# EFM32WG980F256 register map
File version: 4.0.0
CPU: CM4 r0p1, little endian, MPU, FPU, 3 interrupt priority bits
Registers are 32-bit, read-write, reset 0x0 unless marked. A register's access mark holds for its fields unless they carry their own. Offsets are from the block's base; [hi:lo] are bit positions; {n}, {i} and the like mark numbered series.

## VCMP
Base 0x40000000
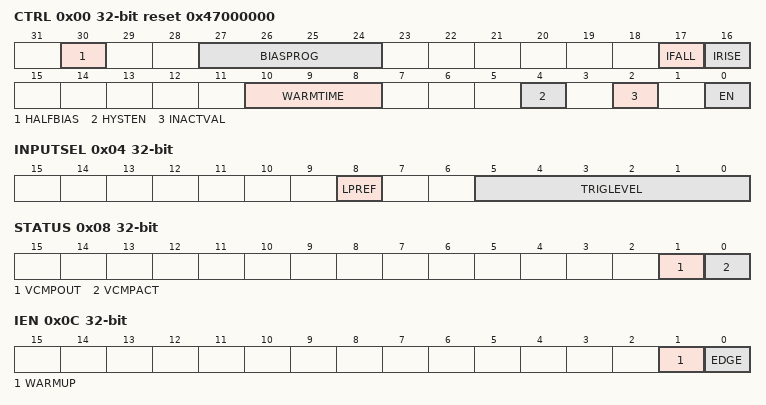
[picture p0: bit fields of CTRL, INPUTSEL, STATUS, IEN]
0x00 CTRL reset 0x47000000 — Control Register
  [30] HALFBIAS — Half Bias Current
  [27:24] BIASPROG — VCMP Bias Programming Value
  [17] IFALL — Falling Edge Interrupt Sense
  [16] IRISE — Rising Edge Interrupt Sense
  [10:8] WARMTIME — Warm-Up Time
    0=4CYCLES (4 HFPERCLK cycles); 1=8CYCLES (8 HFPERCLK cycles); 2=16CYCLES (16 HFPERCLK cycles); 3=32CYCLES (32 HFPERCLK cycles); 4=64CYCLES (64 HFPERCLK cycles); 5=128CYCLES (128 HFPERCLK cycles); 6=256CYCLES (256 HFPERCLK cycles); 7=512CYCLES (512 HFPERCLK cycles)
  [4] HYSTEN — Hysteresis Enable
  [2] INACTVAL — Inactive Value
  [0] EN — Voltage Supply Comparator Enable
0x04 INPUTSEL — Input Selection Register
  [8] LPREF — Low Power Reference
  [5:0] TRIGLEVEL — Trigger Level
0x08 STATUS ro
  [1] VCMPOUT — Voltage Supply Comparator Output
  [0] VCMPACT — Voltage Supply Comparator Active
0x0C IEN — Interrupt Enable Register
  [1] WARMUP — Warm-up Interrupt Enable
  [0] EDGE — Edge Trigger Interrupt Enable
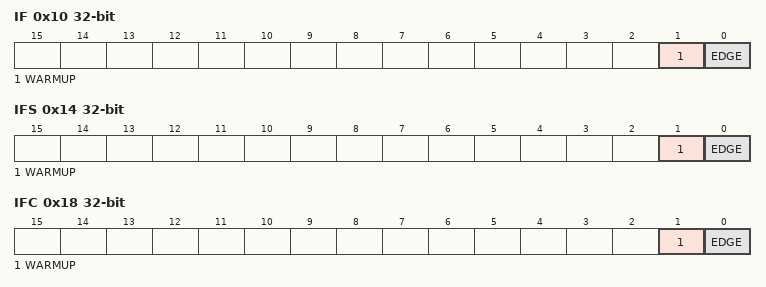
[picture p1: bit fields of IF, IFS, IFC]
0x10 IF ro — Interrupt Flag Register
  [1] WARMUP — Warm-up Interrupt Flag
  [0] EDGE — Edge Triggered Interrupt Flag
0x14 IFS wo — Interrupt Flag Set Register
  [1] WARMUP — Warm-up Interrupt Flag Set
  [0] EDGE — Edge Triggered Interrupt Flag Set
0x18 IFC wo — Interrupt Flag Clear Register
  [1] WARMUP — Warm-up Interrupt Flag Clear
  [0] EDGE — Edge Triggered Interrupt Flag Clear

## PRS
Base 0x400CC000
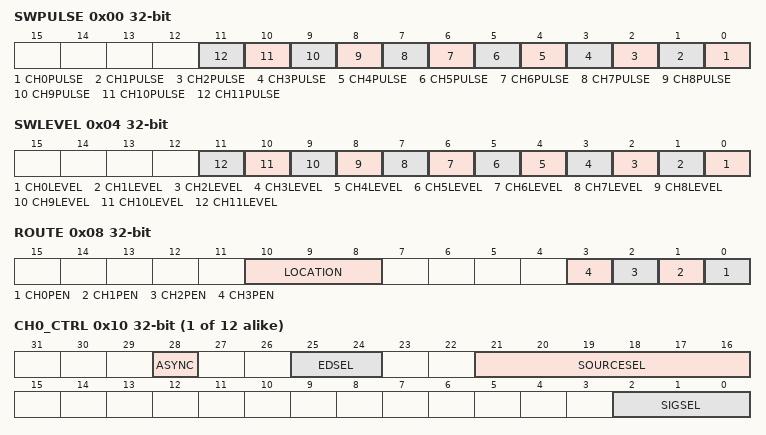
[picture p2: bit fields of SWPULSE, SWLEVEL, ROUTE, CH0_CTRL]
0x00 SWPULSE wo — Software Pulse Register
  [n] CH{n}PULSE (n=0..11) — Channel {n} Pulse Generation
0x04 SWLEVEL — Software Level Register
  [n] CH{n}LEVEL (n=0..11) — Channel {n} Software Level
0x08 ROUTE — I/O Routing Register
  [10:8] LOCATION — I/O Location
    0=LOC0 (Location 0); 1=LOC1 (Location 1)
  [n] CH{n}PEN (n=0..3) — CH{n} Pin Enable
{0x10+4i} CH{i}_CTRL (i=0..11) — Channel Control Register
  [28] ASYNC — Asynchronous reflex
  [25:24] EDSEL — Edge Detect Select
    0=OFF (Signal is left as it is); 1=POSEDGE (A one HFPERCLK cycle pulse is generated for every positive edge of the incoming signal); 2=NEGEDGE (A one HFPERCLK clock cycle pulse is generated for every negative edge of the incoming signal); 3=BOTHEDGES (A one HFPERCLK clock cycle pulse is generated for every edge of the incoming signal)
  [21:16] SOURCESEL — Source Select
    0=NONE (No source selected); 1=VCMP (Voltage Comparator); 2=ACMP0 (Analog Comparator 0); 3=ACMP1 (Analog Comparator 1); 6=DAC0 (Digital to Analog Converter 0); 8=ADC0 (Analog to Digital Converter 0); 16=USART0 (Universal Synchronous/Asynchronous Receiver/Transmitter 0); 17=USART1 (Universal Synchronous/Asynchronous Receiver/Transmitter 1); 18=USART2 (Universal Synchronous/Asynchronous Receiver/Transmitter 2); {v}=TIMER{v-28} (v=28..31); 36=USB (Universal Serial Bus Interface); 40=RTC (Real-Time Counter); 41=UART0 (Universal Asynchronous Receiver/Transmitter 0); 42=UART1 (Universal Asynchronous Receiver/Transmitter 1); 48=GPIOL (General purpose Input/Output); 49=GPIOH (General purpose Input/Output); 52=LETIMER0 (Low Energy Timer 0); 55=BURTC (Backup RTC); 57=LESENSEL (Low Energy Sensor Interface); 58=LESENSEH (Low Energy Sensor Interface); 59=LESENSED (Low Energy Sensor Interface)
  [2:0] SIGSEL — Signal Select

## LCD
Base 0x4008A000
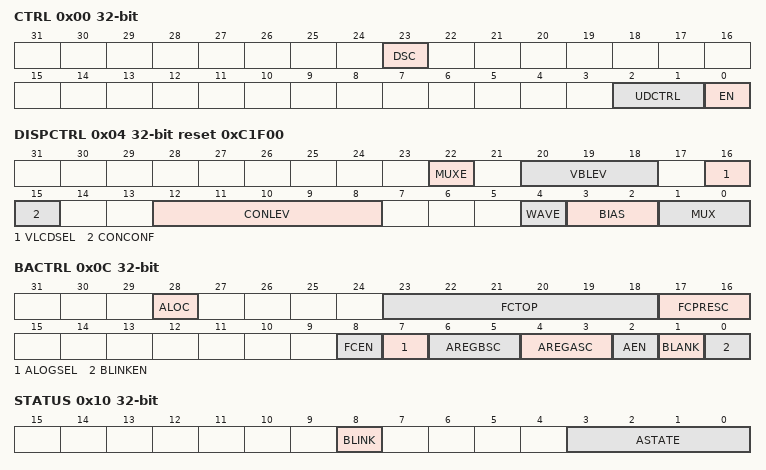
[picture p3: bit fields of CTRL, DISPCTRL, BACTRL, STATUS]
0x00 CTRL — Control Register
  [23] DSC — Direct Segment Control
  [2:1] UDCTRL — Update Data Control
    0=REGULAR (The data transfer is controlled by SW. Transfer is performed as soon as possible); 1=FCEVENT (The data transfer is done at the next event triggered by the Frame Counter); 2=FRAMESTART (The data transfer is done continuously at every LCD frame start)
  [0] EN — LCD Enable
0x04 DISPCTRL reset 0xC1F00 — Display Control Register
  [22] MUXE — Extended Mux Configuration
  [20:18] VBLEV — Voltage Boost Level
    0=LEVEL0 (Minimum boost level); {v}=LEVEL{v} (v=1..6); 7=LEVEL7 (Maximum boost level)
  [16] VLCDSEL — VLCD Selection
  [15] CONCONF — Contrast Configuration
  [12:8] CONLEV — Contrast Level
    0=MIN (Minimum contrast); 31=MAX (Maximum contrast)
  [4] WAVE — Waveform Selection
  [3:2] BIAS — Bias Configuration
    0=STATIC; 1=ONEHALF (1/2 Bias); 2=ONETHIRD (1/3 Bias); 3=ONEFOURTH (1/4 Bias)
  [1:0] MUX — Mux Configuration
    0=STATIC; 1=DUPLEX; 2=TRIPLEX; 3=QUADRUPLEX
0x08 SEGEN — Segment Enable Register
  [9:0] SEGEN — Segment Enable
0x0C BACTRL — Blink and Animation Control Register
  [28] ALOC — Animation Location
  [23:18] FCTOP — Frame Counter Top Value
  [17:16] FCPRESC — Frame Counter Prescaler
    0=DIV1 (CLKFC = CLKFRAME / 1); 1=DIV2 (CLKFC = CLKFRAME / 2); 2=DIV4 (CLKFC = CLKFRAME / 4); 3=DIV8 (CLKFC = CLKFRAME / 8)
  [8] FCEN — Frame Counter Enable
  [7] ALOGSEL — Animate Logic Function Select
  [6:5] AREGBSC — Animate Register B Shift Control
    0=NOSHIFT (No Shift operation on Animation Register B); 1=SHIFTLEFT (Animation Register B is shifted left); 2=SHIFTRIGHT (Animation Register B is shifted right)
  [4:3] AREGASC — Animate Register A Shift Control
    0=NOSHIFT (No Shift operation on Animation Register A); 1=SHIFTLEFT (Animation Register A is shifted left); 2=SHIFTRIGHT (Animation Register A is shifted right)
  [2] AEN — Animation Enable
  [1] BLANK — Blank Display
  [0] BLINKEN — Blink Enable
0x10 STATUS ro
  [8] BLINK — Blink State
  [3:0] ASTATE — Current Animation State
0x14 AREGA — Animation Register A
  [7:0] AREGA — Animation Register A Data
0x18 AREGB — Animation Register B
  [7:0] AREGB — Animation Register B Data
0x1C IF ro — Interrupt Flag Register
  [0] FC — Frame Counter Interrupt Flag
0x20 IFS wo — Interrupt Flag Set Register
  [0] FC — Frame Counter Interrupt Flag Set
0x24 IFC wo — Interrupt Flag Clear Register
  [0] FC — Frame Counter Interrupt Flag Clear
0x28 IEN — Interrupt Enable Register
  [0] FC — Frame Counter Interrupt Enable
{0x40+4i} SEGD{i}L (i=0..3) — Segment Data Low Register {i}
  [31:0] SEGD{i}L — COM{i} Segment Data Low
{0x50+4i} SEGD{i}H (i=0..3) — Segment Data High Register {i}
  [7:0] SEGD{i}H — COM{i} Segment Data High
0x60 FREEZE
  [0] REGFREEZE — Register Update Freeze
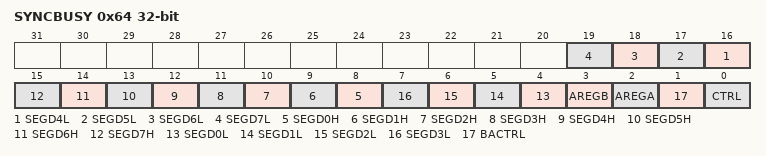
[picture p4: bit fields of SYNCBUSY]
0x64 SYNCBUSY ro — Synchronization Busy Register
  [n+12] SEGD{n}L (n=4..7) — SEGD{n}L Register Busy
  [n+8] SEGD{n}H (n=0..7) — SEGD{n}H Register Busy
  [n+4] SEGD{n}L (n=0..3) — SEGD{n}L Register Busy
  [3] AREGB — AREGB Register Busy
  [2] AREGA — AREGA Register Busy
  [1] BACTRL — BACTRL Register Busy
  [0] CTRL — CTRL Register Busy
{0xA4+4i} SEGD{i}H (i=4..7) — Segment Data High Register {i}
  [7:0] SEGD{i}H — COM{i-4} Segment Data High
{0xBC+4i} SEGD{i}L (i=4..7) — Segment Data Low Register {i}
  [31:0] SEGD{i}L — COM{i} Segment Data

## WDOG
Base 0x40088000
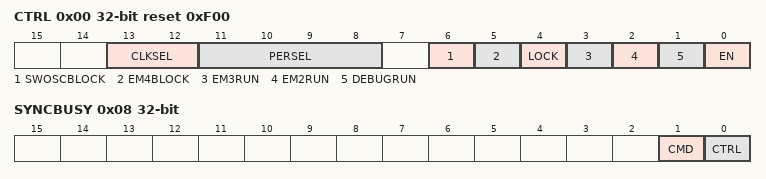
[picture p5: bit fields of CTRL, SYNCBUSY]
0x00 CTRL reset 0xF00 — Control Register
  [13:12] CLKSEL — Watchdog Clock Select
    0=ULFRCO; 1=LFRCO; 2=LFXO
  [11:8] PERSEL — Watchdog Timeout Period Select
  [6] SWOSCBLOCK — Software Oscillator Disable Block
  [5] EM4BLOCK — Energy Mode 4 Block
  [4] LOCK — Configuration lock
  [3] EM3RUN — Energy Mode 3 Run Enable
  [2] EM2RUN — Energy Mode 2 Run Enable
  [1] DEBUGRUN — Debug Mode Run Enable
  [0] EN — Watchdog Timer Enable
0x04 CMD wo — Command Register
  [0] CLEAR — Watchdog Timer Clear
0x08 SYNCBUSY ro — Synchronization Busy Register
  [1] CMD — CMD Register Busy
  [0] CTRL — CTRL Register Busy

## Notices in the file
# License
Copyright 2021 Silicon Laboratories Inc. www.silabs.com
SPDX-License-Identifier: Zlib
The licensor of this software is Silicon Laboratories Inc.
This software is provided 'as-is', without any express or implied
warranty. In no event will the authors be held liable for any damages
arising from the use of this software.
Permission is granted to anyone to use this software for any purpose,
including commercial applications, and to alter it and redistribute it
freely, subject to the following restrictions:
1. The origin of this software must not be misrepresented; you must not
claim that you wrote the original software. If you use this software
in a product, an acknowledgment in the product documentation would be
appreciated but is not required.
2. Altered source versions must be plainly marked as such, and must not be
misrepresented as being the original software.
3. This notice may not be removed or altered from any source distribution.
